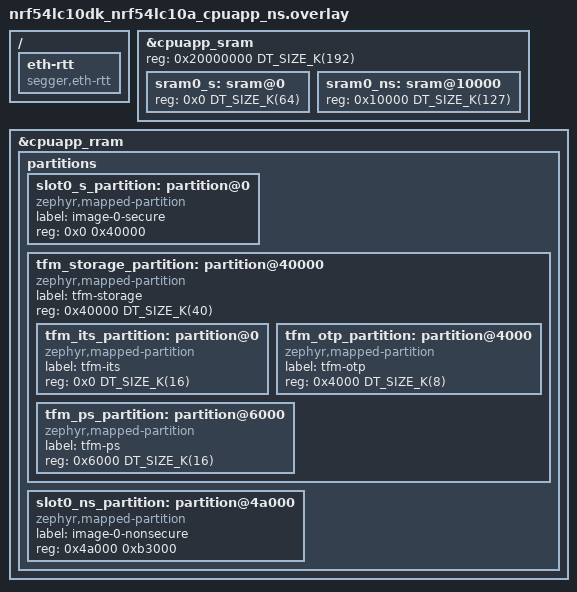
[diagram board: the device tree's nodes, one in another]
/*
 * Copyright (c) 2026 Nordic Semiconductor
 *
 * SPDX-License-Identifier: LicenseRef-Nordic-5-Clause
 */

/delete-node/ &slot0_partition;
/delete-node/ &slot0_ns_partition;
/delete-node/ &storage_partition;

/delete-node/ &tfm_its_partition;
/delete-node/ &tfm_otp_partition;
/delete-node/ &tfm_ps_partition;

/delete-node/ &sram0_s;
/delete-node/ &sram0_ns;

/* Rebalance the secure/non-secure SRAM split to 64 kB / 127 kB so the
 * non-secure image (psa_tls needs ~115 kB of RAM) fits. nRF54LC10A has
 * 192 kB total SRAM; 1 kB at the top is left unused to match the upstream
 * TF-M layout.
 */
&cpuapp_sram {
	reg = <0x20000000 DT_SIZE_K(192)>;
	ranges = <0x0 0x20000000 0x20030000>;

	sram0_s: sram@0 {
		#address-cells = <1>;
		#size-cells = <1>;
		/* Secure image memory */
		reg = <0x0 DT_SIZE_K(64)>;
		ranges = <0x0 0x0 DT_SIZE_K(64)>;
	};

	sram0_ns: sram@10000 {
		#address-cells = <1>;
		#size-cells = <1>;
		/* Non-Secure image memory */
		reg = <0x10000 DT_SIZE_K(127)>;
		ranges = <0x0 0x10000 DT_SIZE_K(127)>;
	};
};

&cpuapp_rram {
	partitions {
		#address-cells = <1>;
		#size-cells = <1>;
		ranges;

		slot0_s_partition: partition@0 {
			compatible = "zephyr,mapped-partition";
			label = "image-0-secure";
			reg = <0x0 0x40000>;
		};

		tfm_storage_partition: partition@40000 {
			compatible = "zephyr,mapped-partition";
			label = "tfm-storage";
			reg = <0x40000 DT_SIZE_K(40)>;
			ranges = <0x0 0x40000 DT_SIZE_K(40)>;
			#address-cells = <1>;
			#size-cells = <1>;

			tfm_its_partition: partition@0 {
				compatible = "zephyr,mapped-partition";
				label = "tfm-its";
				reg = <0x0 DT_SIZE_K(16)>;
			};

			tfm_otp_partition: partition@4000 {
				compatible = "zephyr,mapped-partition";
				label = "tfm-otp";
				reg = <0x4000 DT_SIZE_K(8)>;
			};

			tfm_ps_partition: partition@6000 {
				compatible = "zephyr,mapped-partition";
				label = "tfm-ps";
				reg = <0x6000 DT_SIZE_K(16)>;
			};
		};

		slot0_ns_partition: partition@4a000 {
			compatible = "zephyr,mapped-partition";
			label = "image-0-nonsecure";
			reg = <0x4a000 0xb3000>;
		};
	};
};

/ {
	eth-rtt {
		compatible = "segger,eth-rtt";
	};
};
